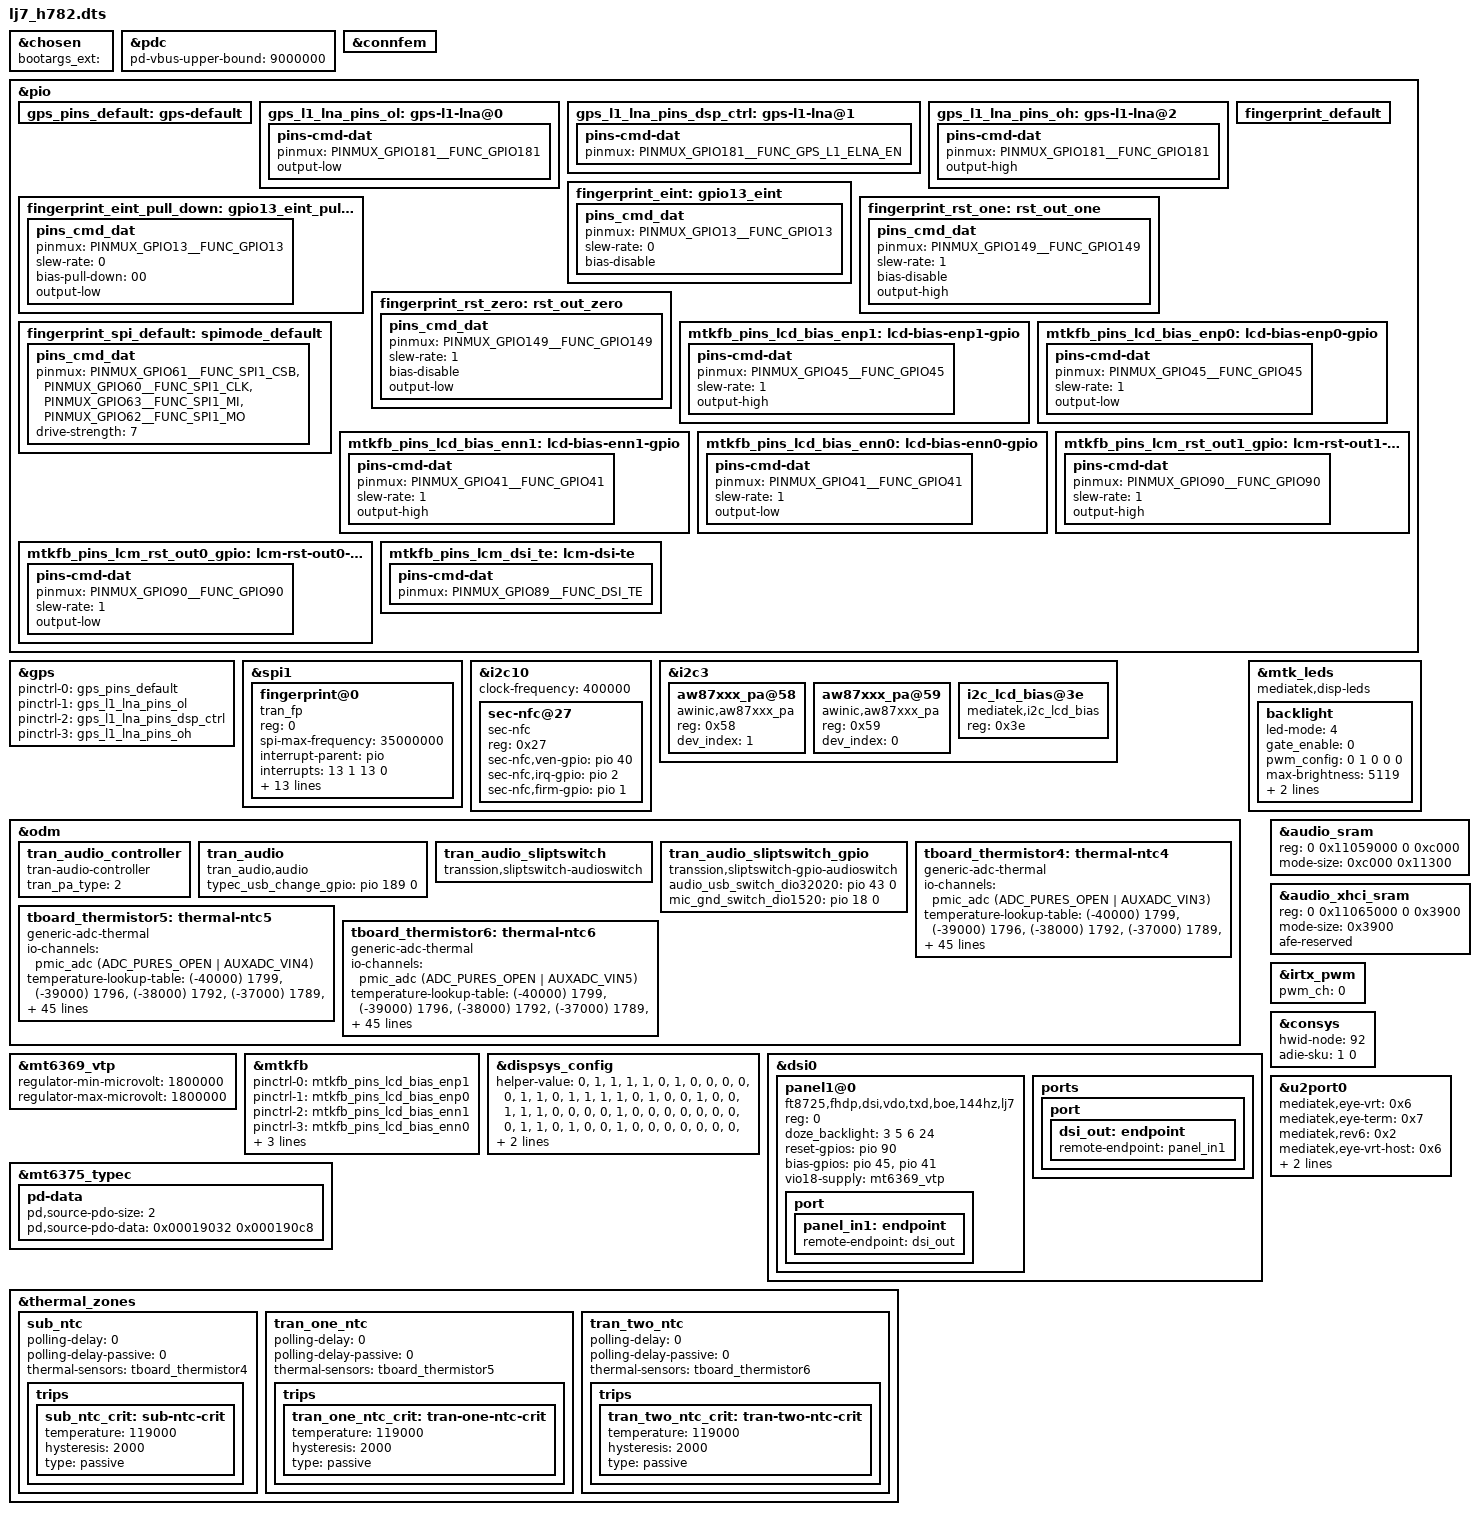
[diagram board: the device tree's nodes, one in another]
// SPDX-License-Identifier: (GPL-2.0 OR MIT)
/*
 * Copyright (C) 2022 MediaTek Inc.
 */
/dts-v1/;
/plugin/;
#include <dt-bindings/interrupt-controller/arm-gic.h>
#include <dt-bindings/interrupt-controller/irq.h>
#include <dt-bindings/phy/phy.h>
#include <dt-bindings/pinctrl/mt6878-pinfunc.h>
#include <dt-bindings/iio/mt635x-auxadc.h> 
#if 0
#include <dt-bindings/pinctrl/mt6897-pinfunc.h>
#endif

&chosen {
bootargs_ext = "";
};

&pdc {
	pd-vbus-upper-bound = <9000000>;
};

#if 1

&connfem {
/* Enable epa_elna node to support Wifi & BT ePA/eLNA FEM on customer load */
#if 0
	epa-elna {
		parts = <&wlan7207h &wlan7207c>;
		wifi {
			flags-0 {
				open-loop;
			};
		};
		bt {
			flags-0 {
				/* choose one of: epa-elna/epa/elna/bypass */
				epa-elna;
			};
		};
	};
#endif
};

/* GPS GPIO standardization start */
&pio {
	gps_pins_default: gps-default {
	};
	gps_l1_lna_pins_ol: gps-l1-lna@0 {
		pins-cmd-dat {
			pinmux = <PINMUX_GPIO181__FUNC_GPIO181>;
			output-low;
		};
	};
	gps_l1_lna_pins_dsp_ctrl: gps-l1-lna@1 {
		pins-cmd-dat {
			pinmux = <PINMUX_GPIO181__FUNC_GPS_L1_ELNA_EN>;
		};
	};
	gps_l1_lna_pins_oh: gps-l1-lna@2 {
		pins-cmd-dat {
			pinmux = <PINMUX_GPIO181__FUNC_GPIO181>;
			output-high;
		};
	};
};
&gps {
	pinctrl-names = "default",
		"gps_l1_lna_disable",
		"gps_l1_lna_dsp_ctrl",
		"gps_l1_lna_enable";
	pinctrl-0 = <&gps_pins_default>;
	pinctrl-1 = <&gps_l1_lna_pins_ol>;
	pinctrl-2 = <&gps_l1_lna_pins_dsp_ctrl>;
	pinctrl-3 = <&gps_l1_lna_pins_oh>;
	status = "okay";
};
/* GPS GPIO standardization end */

#endif

&spi1 {
    fingerprint@0 {
        compatible = "tran_fp";
        reg = <0>;
        spi-max-frequency = <35000000>;
        interrupt-parent = <&pio>;
        interrupts = <13 1 13 0>;
        debounce = <27 0>;
        irq-gpio = <13>;
        irq-gpio-std = <&pio 13 0x0>;
        reset-gpio = <149>;
        reset-gpio-std = <&pio 149 0x0>;
        vmch-supply = <&mt6369_vfp>;
        fod_location_xy = "630,2537";
        pinctrl-names ="tran_fp_default",
            "tran_fp_pin_irq",
            "tran_fp_irq_pull_down",
            "tran_fp_reset_high",
            "tran_fp_reset_low",
            "tran_fp_spi_default";
        pinctrl-0 = <&fingerprint_default>;
        pinctrl-1 = <&fingerprint_eint>;
        pinctrl-2 = <&fingerprint_eint_pull_down>;
        pinctrl-3 = <&fingerprint_rst_one>;
        pinctrl-4 = <&fingerprint_rst_zero>;
        pinctrl-5 = <&fingerprint_spi_default>;
        status = "okay";
    };
};
&pio {
    fingerprint_default: fingerprint_default {
	};
    fingerprint_eint: gpio13_eint {
    pins_cmd_dat {
        pinmux = <PINMUX_GPIO13__FUNC_GPIO13>;
        slew-rate = <0>;
        bias-disable;
        };
    };
    fingerprint_eint_pull_down: gpio13_eint_pull_down {
    pins_cmd_dat {
        pinmux = <PINMUX_GPIO13__FUNC_GPIO13>;
        slew-rate = <0>;
        bias-pull-down = <00>;
        output-low;
        };
    };
    fingerprint_rst_one: rst_out_one {
    pins_cmd_dat {
        pinmux = <PINMUX_GPIO149__FUNC_GPIO149>;
        slew-rate = <1>;
        bias-disable;
        output-high;
        };
    };
    fingerprint_rst_zero: rst_out_zero {
    pins_cmd_dat {
        pinmux = <PINMUX_GPIO149__FUNC_GPIO149>;
        slew-rate = <1>;
        bias-disable;
        output-low;
        };
    };
    fingerprint_spi_default: spimode_default {
        pins_cmd_dat {
        pinmux = <PINMUX_GPIO61__FUNC_SPI1_CSB>,
                <PINMUX_GPIO60__FUNC_SPI1_CLK>,
                <PINMUX_GPIO63__FUNC_SPI1_MI>,
                <PINMUX_GPIO62__FUNC_SPI1_MO>;
                drive-strength = <7>;
         };
     };
};

&i2c10 {
	clock-frequency = <400000>;
	sec-nfc@27 {
		compatible = "sec-nfc";
		reg = <0x27>;
		sec-nfc,ven-gpio = <&pio 40 0x0>;
		sec-nfc,irq-gpio = <&pio 2 0x0>;
		sec-nfc,firm-gpio = <&pio 1 0x0>;
	};
};

/*
&i2c6 {
	spk: speaker-amp@5c {
		compatible = "richtek,rt5512";
		#address-cells = <1>;
		#size-cells = <0>;
		#sound-dai-cells = <0>;
		reg = <0x5c>;
		status = "okay";
		sound-name-prefix = "Left";
	};
};
&sound {
	mediatek,spk-i2s = <25 24>;
};
*/
&i2c3 {
	aw87xxx_pa@58 {
		compatible = "awinic,aw87xxx_pa";
		reg = <0x58>;
		dev_index = < 1 >;
		status = "okay";
	};
	aw87xxx_pa@59 {
		compatible = "awinic,aw87xxx_pa";
		reg = <0x59>;
		dev_index = < 0 >;
		status = "okay";
	};
};

&odm {
	tran_audio_controller:tran_audio_controller {
		compatible = "tran-audio-controller";
		tran_pa_type = <2>;
	};
	tran_audio:tran_audio {
		compatible = "tran_audio,audio";
		typec_usb_change_gpio = <&pio 189 0>;
	};
	tran_audio_sliptswitch {
		compatible = "transsion,sliptswitch-audioswitch";
	};
	tran_audio_sliptswitch_gpio {
		compatible = "transsion,sliptswitch-gpio-audioswitch";
		audio_usb_switch_dio32020 = <&pio 43 0>;
		mic_gnd_switch_dio1520 = <&pio 18 0>;
	};
	tboard_thermistor4: thermal-ntc4 {
		compatible = "generic-adc-thermal";
		#thermal-sensor-cells = <0>;
		io-channels = <&pmic_adc (ADC_PURES_OPEN | AUXADC_VIN3)>;
		io-channel-names = "sensor-channel";
		temperature-lookup-table =
            <(-40000) 1799>,
			<(-39000) 1796>,
			<(-38000) 1792>,
			<(-37000) 1789>,
			<(-36000) 1786>,
			<(-35000) 1782>,
			<(-34000) 1778>,
			<(-33000) 1774>,
			<(-32000) 1769>,
			<(-31000) 1764>,
			<(-30000) 1759>,
			<(-29000) 1754>,
			<(-28000) 1749>,
			<(-27000) 1743>,
			<(-26000) 1737>,
			<(-25000) 1730>,
			<(-24000) 1723>,
			<(-23000) 1716>,
			<(-22000) 1709>,
			<(-21000) 1701>,
			<(-20000) 1692>,
			<(-19000) 1684>,
			<(-18000) 1675>,
			<(-17000) 1665>,
			<(-16000) 1655>,
			<(-15000) 1645>,
			<(-14000) 1634>,
			<(-13000) 1623>,
			<(-12000) 1612>,
			<(-11000) 1600>,
			<(-10000) 1587>,
			<(-9000) 1574>,
			<(-8000) 1561>,
			<(-7000) 1547>,
			<(-6000) 1532>,
			<(-5000) 1518>,
			<(-4000) 1502>,
			<(-3000) 1487>,
			<(-2000) 1471>,
			<(-1000) 1454>,
			<0 1437>,
			<1000 1419>,
			<2000 1402>,
			<3000 1383>,
			<4000 1365>,
			<5000 1346>,
			<6000 1326>,
			<7000 1306>,
			<8000 1286>,
			<9000 1266>,
			<10000 1245>,
			<11000 1225>,
			<12000 1203>,
			<13000 1182>,
			<14000 1161>,
			<15000 1139>,
			<16000 1117>,
			<17000 1095>,
			<18000 1073>,
			<19000 1051>,
			<20000 1029>,
			<21000 1007>,
			<22000 985>,
			<23000 963>,
			<24000 941>,
			<25000 920>,
			<26000 898>,
			<27000 876>,
			<28000 855>,
			<29000 834>,
			<30000 813>,
			<31000 792>,
			<32000 772>,
			<33000 751>,
			<34000 731>,
			<35000 712>,
			<36000 692>,
			<37000 673>,
			<38000 655>,
			<39000 636>,
			<40000 618>,
			<41000 601>,
			<42000 583>,
			<43000 566>,
			<44000 550>,
			<45000 534>,
			<46000 518>,
			<47000 502>,
			<48000 487>,
			<49000 472>,
			<50000 458>,
			<51000 444>,
			<52000 430>,
			<53000 417>,
			<54000 404>,
			<55000 392>,
			<56000 380>,
			<57000 368>,
			<58000 356>,
			<59000 345>,
			<60000 334>,
			<61000 324>,
			<62000 313>,
			<63000 303>,
			<64000 294>,
			<65000 284>,
			<66000 275>,
			<67000 267>,
			<68000 258>,
			<69000 250>,
			<70000 242>,
			<71000 234>,
			<72000 227>,
			<73000 220>,
			<74000 213>,
			<75000 206>,
			<76000 199>,
			<77000 193>,
			<78000 187>,
			<79000 181>,
			<80000 175>,
			<81000 170>,
			<82000 164>,
			<83000 159>,
			<84000 154>,
			<85000 149>,
			<86000 145>,
			<87000 140>,
			<88000 136>,
			<89000 132>,
			<90000 128>,
			<91000 124>,
			<92000 120>,
			<93000 116>,
			<94000 113>,
			<95000 109>,
			<96000 106>,
			<97000 103>,
			<98000 99>,
			<99000 96>,
			<100000 94>,
			<101000 91>,
			<102000 88>,
			<103000 85>,
			<104000 83>,
			<105000 80>,
			<106000 78>,
			<107000 76>,
			<108000 73>,
			<109000 71>,
			<110000 69>,
			<111000 67>,
			<112000 65>,
			<113000 63>,
			<114000 61>,
			<115000 60>,
			<116000 58>,
			<117000 56>,
			<118000 55>,
			<119000 53>,
			<120000 52>,
			<121000 50>,
			<122000 49>,
			<123000 47>,
			<124000 46>,
			<125000 45>;
	};

	tboard_thermistor5: thermal-ntc5 {
		compatible = "generic-adc-thermal";
		#thermal-sensor-cells = <0>;
		io-channels = <&pmic_adc (ADC_PURES_OPEN | AUXADC_VIN4)>;
		io-channel-names = "sensor-channel";
		temperature-lookup-table =
            <(-40000) 1799>,
			<(-39000) 1796>,
			<(-38000) 1792>,
			<(-37000) 1789>,
			<(-36000) 1786>,
			<(-35000) 1782>,
			<(-34000) 1778>,
			<(-33000) 1774>,
			<(-32000) 1769>,
			<(-31000) 1764>,
			<(-30000) 1759>,
			<(-29000) 1754>,
			<(-28000) 1749>,
			<(-27000) 1743>,
			<(-26000) 1737>,
			<(-25000) 1730>,
			<(-24000) 1723>,
			<(-23000) 1716>,
			<(-22000) 1709>,
			<(-21000) 1701>,
			<(-20000) 1692>,
			<(-19000) 1684>,
			<(-18000) 1675>,
			<(-17000) 1665>,
			<(-16000) 1655>,
			<(-15000) 1645>,
			<(-14000) 1634>,
			<(-13000) 1623>,
			<(-12000) 1612>,
			<(-11000) 1600>,
			<(-10000) 1587>,
			<(-9000) 1574>,
			<(-8000) 1561>,
			<(-7000) 1547>,
			<(-6000) 1532>,
			<(-5000) 1518>,
			<(-4000) 1502>,
			<(-3000) 1487>,
			<(-2000) 1471>,
			<(-1000) 1454>,
			<0 1437>,
			<1000 1419>,
			<2000 1402>,
			<3000 1383>,
			<4000 1365>,
			<5000 1346>,
			<6000 1326>,
			<7000 1306>,
			<8000 1286>,
			<9000 1266>,
			<10000 1245>,
			<11000 1225>,
			<12000 1203>,
			<13000 1182>,
			<14000 1161>,
			<15000 1139>,
			<16000 1117>,
			<17000 1095>,
			<18000 1073>,
			<19000 1051>,
			<20000 1029>,
			<21000 1007>,
			<22000 985>,
			<23000 963>,
			<24000 941>,
			<25000 920>,
			<26000 898>,
			<27000 876>,
			<28000 855>,
			<29000 834>,
			<30000 813>,
			<31000 792>,
			<32000 772>,
			<33000 751>,
			<34000 731>,
			<35000 712>,
			<36000 692>,
			<37000 673>,
			<38000 655>,
			<39000 636>,
			<40000 618>,
			<41000 601>,
			<42000 583>,
			<43000 566>,
			<44000 550>,
			<45000 534>,
			<46000 518>,
			<47000 502>,
			<48000 487>,
			<49000 472>,
			<50000 458>,
			<51000 444>,
			<52000 430>,
			<53000 417>,
			<54000 404>,
			<55000 392>,
			<56000 380>,
			<57000 368>,
			<58000 356>,
			<59000 345>,
			<60000 334>,
			<61000 324>,
			<62000 313>,
			<63000 303>,
			<64000 294>,
			<65000 284>,
			<66000 275>,
			<67000 267>,
			<68000 258>,
			<69000 250>,
			<70000 242>,
			<71000 234>,
			<72000 227>,
			<73000 220>,
			<74000 213>,
			<75000 206>,
			<76000 199>,
			<77000 193>,
			<78000 187>,
			<79000 181>,
			<80000 175>,
			<81000 170>,
			<82000 164>,
			<83000 159>,
			<84000 154>,
			<85000 149>,
			<86000 145>,
			<87000 140>,
			<88000 136>,
			<89000 132>,
			<90000 128>,
			<91000 124>,
			<92000 120>,
			<93000 116>,
			<94000 113>,
			<95000 109>,
			<96000 106>,
			<97000 103>,
			<98000 99>,
			<99000 96>,
			<100000 94>,
			<101000 91>,
			<102000 88>,
			<103000 85>,
			<104000 83>,
			<105000 80>,
			<106000 78>,
			<107000 76>,
			<108000 73>,
			<109000 71>,
			<110000 69>,
			<111000 67>,
			<112000 65>,
			<113000 63>,
			<114000 61>,
			<115000 60>,
			<116000 58>,
			<117000 56>,
			<118000 55>,
			<119000 53>,
			<120000 52>,
			<121000 50>,
			<122000 49>,
			<123000 47>,
			<124000 46>,
			<125000 45>;
	};

	tboard_thermistor6: thermal-ntc6 {
		compatible = "generic-adc-thermal";
		#thermal-sensor-cells = <0>;
		io-channels = <&pmic_adc (ADC_PURES_OPEN | AUXADC_VIN5)>;
		io-channel-names = "sensor-channel";
		temperature-lookup-table =
            <(-40000) 1799>,
			<(-39000) 1796>,
			<(-38000) 1792>,
			<(-37000) 1789>,
			<(-36000) 1786>,
			<(-35000) 1782>,
			<(-34000) 1778>,
			<(-33000) 1774>,
			<(-32000) 1769>,
			<(-31000) 1764>,
			<(-30000) 1759>,
			<(-29000) 1754>,
			<(-28000) 1749>,
			<(-27000) 1743>,
			<(-26000) 1737>,
			<(-25000) 1730>,
			<(-24000) 1723>,
			<(-23000) 1716>,
			<(-22000) 1709>,
			<(-21000) 1701>,
			<(-20000) 1692>,
			<(-19000) 1684>,
			<(-18000) 1675>,
			<(-17000) 1665>,
			<(-16000) 1655>,
			<(-15000) 1645>,
			<(-14000) 1634>,
			<(-13000) 1623>,
			<(-12000) 1612>,
			<(-11000) 1600>,
			<(-10000) 1587>,
			<(-9000) 1574>,
			<(-8000) 1561>,
			<(-7000) 1547>,
			<(-6000) 1532>,
			<(-5000) 1518>,
			<(-4000) 1502>,
			<(-3000) 1487>,
			<(-2000) 1471>,
			<(-1000) 1454>,
			<0 1437>,
			<1000 1419>,
			<2000 1402>,
			<3000 1383>,
			<4000 1365>,
			<5000 1346>,
			<6000 1326>,
			<7000 1306>,
			<8000 1286>,
			<9000 1266>,
			<10000 1245>,
			<11000 1225>,
			<12000 1203>,
			<13000 1182>,
			<14000 1161>,
			<15000 1139>,
			<16000 1117>,
			<17000 1095>,
			<18000 1073>,
			<19000 1051>,
			<20000 1029>,
			<21000 1007>,
			<22000 985>,
			<23000 963>,
			<24000 941>,
			<25000 920>,
			<26000 898>,
			<27000 876>,
			<28000 855>,
			<29000 834>,
			<30000 813>,
			<31000 792>,
			<32000 772>,
			<33000 751>,
			<34000 731>,
			<35000 712>,
			<36000 692>,
			<37000 673>,
			<38000 655>,
			<39000 636>,
			<40000 618>,
			<41000 601>,
			<42000 583>,
			<43000 566>,
			<44000 550>,
			<45000 534>,
			<46000 518>,
			<47000 502>,
			<48000 487>,
			<49000 472>,
			<50000 458>,
			<51000 444>,
			<52000 430>,
			<53000 417>,
			<54000 404>,
			<55000 392>,
			<56000 380>,
			<57000 368>,
			<58000 356>,
			<59000 345>,
			<60000 334>,
			<61000 324>,
			<62000 313>,
			<63000 303>,
			<64000 294>,
			<65000 284>,
			<66000 275>,
			<67000 267>,
			<68000 258>,
			<69000 250>,
			<70000 242>,
			<71000 234>,
			<72000 227>,
			<73000 220>,
			<74000 213>,
			<75000 206>,
			<76000 199>,
			<77000 193>,
			<78000 187>,
			<79000 181>,
			<80000 175>,
			<81000 170>,
			<82000 164>,
			<83000 159>,
			<84000 154>,
			<85000 149>,
			<86000 145>,
			<87000 140>,
			<88000 136>,
			<89000 132>,
			<90000 128>,
			<91000 124>,
			<92000 120>,
			<93000 116>,
			<94000 113>,
			<95000 109>,
			<96000 106>,
			<97000 103>,
			<98000 99>,
			<99000 96>,
			<100000 94>,
			<101000 91>,
			<102000 88>,
			<103000 85>,
			<104000 83>,
			<105000 80>,
			<106000 78>,
			<107000 76>,
			<108000 73>,
			<109000 71>,
			<110000 69>,
			<111000 67>,
			<112000 65>,
			<113000 63>,
			<114000 61>,
			<115000 60>,
			<116000 58>,
			<117000 56>,
			<118000 55>,
			<119000 53>,
			<120000 52>,
			<121000 50>,
			<122000 49>,
			<123000 47>,
			<124000 46>,
			<125000 45>;
	};
};

&i2c3 {
	i2c_lcd_bias@3e {
		compatible = "mediatek,i2c_lcd_bias";
		reg = <0x3e>;
		status = "okay";
	};
};

&mtk_leds {
	compatible = "mediatek,disp-leds";

	backlight {
		led-mode = <4>;
		gate_enable = <0>;
		pwm_config = <0 1 0 0 0>;
		max-brightness = <5119>;
		min-brightness = <0>;
		max-hw-brightness = <5119>;
	};
};


&pio {
	mtkfb_pins_lcd_bias_enp1: lcd-bias-enp1-gpio {
		pins-cmd-dat {
			pinmux = <PINMUX_GPIO45__FUNC_GPIO45>;
			slew-rate = <1>;
			output-high;
		};
	};

	mtkfb_pins_lcd_bias_enp0: lcd-bias-enp0-gpio {
		pins-cmd-dat {
			pinmux = <PINMUX_GPIO45__FUNC_GPIO45>;
			slew-rate = <1>;
			output-low;
		};
	};

	mtkfb_pins_lcd_bias_enn1: lcd-bias-enn1-gpio {
		pins-cmd-dat {
			pinmux = <PINMUX_GPIO41__FUNC_GPIO41>;
			slew-rate = <1>;
			output-high;
		};
	};

	mtkfb_pins_lcd_bias_enn0: lcd-bias-enn0-gpio {
		pins-cmd-dat {
			pinmux = <PINMUX_GPIO41__FUNC_GPIO41>;
			slew-rate = <1>;
			output-low;
		};
	};

	mtkfb_pins_lcm_rst_out1_gpio: lcm-rst-out1-gpio {
		pins-cmd-dat {
			pinmux = <PINMUX_GPIO90__FUNC_GPIO90>;
			slew-rate = <1>;
			output-high;
		};
	};

	mtkfb_pins_lcm_rst_out0_gpio: lcm-rst-out0-gpio {
		pins-cmd-dat {
			pinmux = <PINMUX_GPIO90__FUNC_GPIO90>;
			slew-rate = <1>;
			output-low;
		};
	};
	mtkfb_pins_lcm_dsi_te: lcm-dsi-te {
		pins-cmd-dat {
			pinmux = <PINMUX_GPIO89__FUNC_DSI_TE>;
		};
	};
};

&mt6369_vtp {
	regulator-min-microvolt = <1800000>;
	regulator-max-microvolt = <1800000>;
};

&mtkfb {
	pinctrl-names = "lcd_bias_enp1_gpio", "lcd_bias_enp0_gpio",
		"lcd_bias_enn1_gpio", "lcd_bias_enn0_gpio",
		"lcm_rst_out1_gpio", "lcm_rst_out0_gpio",
		"mode_te_te";
	pinctrl-0 = <&mtkfb_pins_lcd_bias_enp1>;
	pinctrl-1 = <&mtkfb_pins_lcd_bias_enp0>;
	pinctrl-2 = <&mtkfb_pins_lcd_bias_enn1>;
	pinctrl-3 = <&mtkfb_pins_lcd_bias_enn0>;
	pinctrl-4 = <&mtkfb_pins_lcm_rst_out1_gpio>;
	pinctrl-5 = <&mtkfb_pins_lcm_rst_out0_gpio>;
	pinctrl-6 = <&mtkfb_pins_lcm_dsi_te>;

	status = "okay";
};

&dispsys_config {
	helper-value = <0>, /*MTK_DRM_OPT_STAGE*/
		<1>, /*MTK_DRM_OPT_USE_CMDQ*/
		<1>, /*MTK_DRM_OPT_USE_M4U*/
		<1>, /*MTK_DRM_OPT_MMQOS_SUPPORT*/
		<1>, /*MTK_DRM_OPT_MMDVFS_SUPPORT*/
		<0>, /*MTK_DRM_OPT_SODI_SUPPORT*/
		<1>, /*MTK_DRM_OPT_IDLE_MGR*/
		<0>, /*MTK_DRM_OPT_IDLEMGR_SWTCH_DECOUPLE*/
		<0>, /*MTK_DRM_OPT_IDLEMGR_BY_REPAINT*/
		<0>, /*MTK_DRM_OPT_IDLEMGR_ENTER_ULPS*/
		<0>, /*MTK_DRM_OPT_IDLEMGR_KEEP_LP11*/
		<0>, /*MTK_DRM_OPT_DYNAMIC_RDMA_GOLDEN_SETTING*/
		<1>, /*MTK_DRM_OPT_IDLEMGR_DISABLE_ROUTINE_IRQ*/
		<1>, /*MTK_DRM_OPT_IDLEMGR_ASYNC*/
		<0>, /*MTK_DRM_OPT_MET_LOG*/
		<1>, /*MTK_DRM_OPT_USE_PQ*/
		<1>, /*MTK_DRM_OPT_ESD_CHECK_RECOVERY*/
		<1>, /*MTK_DRM_OPT_ESD_CHECK_SWITCH*/
		<1>, /*MTK_DRM_OPT_PRESENT_FENCE*/
		<0>, /*MTK_DRM_OPT_RDMA_UNDERFLOW_AEE*/
		<1>, /*MTK_DRM_OPT_DSI_UNDERRUN_AEE*/
		<0>, /*MTK_DRM_OPT_ODDMR_OD_AEE*/
		<0>, /*MTK_DRM_OPT_ODDMR_DMR_AEE*/
		<1>, /*MTK_DRM_OPT_HRT*/
		<0>, /*MTK_DRM_OPT_HRT_MODE*/
		<0>, /*MTK_DRM_OPT_DELAYED_TRIGGER*/
		<1>, /*MTK_DRM_OPT_OVL_EXT_LAYER*/
		<1>, /*MTK_DRM_OPT_AOD*/
		<1>, /*MTK_DRM_OPT_RPO*/
		<0>, /*MTK_DRM_OPT_DUAL_PIPE*/
		<0>, /*MTK_DRM_OPT_DC_BY_HRT*/
		<0>, /*MTK_DRM_OPT_OVL_WCG*/
		<0>, /*MTK_DRM_OPT_OVL_SBCH*/
		<1>, /*MTK_DRM_OPT_COMMIT_NO_WAIT_VBLANK*/
		<0>, /*MTK_DRM_OPT_MET*/
		<0>, /*MTK_DRM_OPT_REG_PARSER_RAW_DUMP*/
		<0>, /*MTK_DRM_OPT_VP_PQ*/
		<0>, /*MTK_DRM_OPT_GAME_PQ*/
		<0>, /*MTK_DRM_OPT_MMPATH*/
		<0>, /*MTK_DRM_OPT_HBM*/
		<0>, /*MTK_DRM_OPT_VDS_PATH_SWITCH*/
		<0>, /*MTK_DRM_OPT_LAYER_REC*/
		<1>, /*MTK_DRM_OPT_CLEAR_LAYER*/
		<1>, /*MTK_DRM_OPT_LFR*/
		<0>, /*MTK_DRM_OPT_SF_PF*/
		<1>, /*MTK_DRM_OPT_DYN_MIPI_CHANGE*/
		<0>, /*MTK_DRM_OPT_PRIM_DUAL_PIPE*/
		<0>, /*MTK_DRM_OPT_MSYNC2_0*/
		<1>, /*MTK_DRM_OPT_MML_PRIMARY*/
		<0>, /*MTK_DRM_OPT_MML_SUPPORT_CMD_MODE*/
		<0>, /*MTK_DRM_OPT_MML_PQ*/
		<0>, /*MTK_DRM_OPT_MML_IR*/
		<0>, /*MTK_DRM_OPT_DUAL_TE*/
		<0>, /*MTK_DRM_OPT_RES_SWITCH*/
		<0>, /*MTK_DRM_OPT_PREFETCH_TE*/
		<0>, /*MTK_DRM_OPT_VIDLE_APSRC_OFF*/
		<0>, /*MTK_DRM_OPT_VIDLE_DSI_PLL_OFF*/
		<0>, /*MTK_DRM_OPT_CHECK_TRIGGER_MERGE*/
		<0>, /*MTK_DRM_OPT_VIRTUAL_DISP*/
		<1>, /*MTK_DRM_OPT_OVL_BW_MONITOR*/
		<0>, /*MTK_DRM_OPT_GPU_CACHE*/
		<1>, /*MTK_DRM_OPT_SPHRT*/
		<1>, /*MTK_DRM_OPT_SDPA_OVL_SWITCH*/
		<0>, /*MTK_DRM_OPT_HRT_BY_LARB*/
		<1>, /*MTK_DRM_OPT_LAYERING_RULE_BY_LARB*/
		<1>, /*MTK_DRM_OPT_RES_SWITCH_ON_AP*/
		<0>, /*MTK_DRM_OPT_TILE_OVERHEAD*/
		<1>, /*MTK_DRM_OPT_VIDLE_TOP_EN*/
		<0>, /*MTK_DRM_OPT_VIDLE_MTCMOS_DT_EN*/
		<1>, /*MTK_DRM_OPT_VIDLE_MMINFRA_DT_EN*/
		<0>, /*MTK_DRM_OPT_VIDLE_DVFS_DT_EN*/
		<0>, /*MTK_DRM_OPT_VIDLE_QOS_DT_EN*/
		<0>, /*MTK_DRM_OPT_VIDLE_GCE_TS_EN*/
		<0>, /*MTK_DRM_OPT_VIDLE_DECOUPLE_MODE*/
		<0>, /*MTK_DRM_OPT_VIDLE_VDO_PANEL*/
		<0>, /*MTK_DRM_OPT_VIDLE_HOME_SCREEN_IDLE*/
		<0>, /*MTK_DRM_OPT_DPC_PRE_TE_EN*/
		<0>; /*"MTK_DRM_OPT_PER_LARB_PORT_PEAK"*/
};

&dsi0 {
	status = "okay";
	#address-cells = <1>;
	#size-cells = <0>;
	panel1@0 {
		compatible = "ft8725,fhdp,dsi,vdo,txd,boe,144hz,lj7";
		reg = <0>;
		doze_backlight = <3 5 6 24>;
		reset-gpios = <&pio 90 0>;
		bias-gpios = <&pio 45 0>, <&pio 41 0>;
		vio18-supply = <&mt6369_vtp>;
		pinctrl-names = "default";
		port {
			panel_in1: endpoint {
				remote-endpoint = <&dsi_out>;
			};
		};
	};

	ports {
		port {
			dsi_out: endpoint {
				remote-endpoint = <&panel_in1>;
			};
		};
	};
};
&audio_sram {
	reg = <0 0x11059000 0 0xc000>;
	mode-size = <0xc000 0x11300>;
};

&audio_xhci_sram {
	reg = <0 0x11065000 0 0x3900>;
	mode-size = <0x3900>;
	afe-reserved;
};

/* usb typec mux start */
&mt6375_typec {
	//tcpc,en-fod;
	pd-data {
		/*
		 * Fixed 5V, 500 mA <0x00019032>
		 * Fixed 5V, 1A <0x00019064>
		 * Fixed 5V, 1.5A <0x00019096>
		 * Fixed 5V, 2A <0x000190c8>
		 * Fixed 5V, 3A <0x0001912c>
		 * Fixed 9V, 500 mA <0x0002d032>
		 * Fixed 9V, 1A <0x0002d064>
		 * Fixed 9V, 2A <0x0002d0c8>
		 * Fixed 9V, 3A <0x0002d12c>
		 * Variable 5-9V, 1A <0x8642d064>
		 * Variable 5-9V, 2A <0x8642d0c8>
		 * Variable 5-9V, 3A <0x8642d12c>
		 * PPS 3V~5.9V, 3A <0xC0761E3C>
		 */
		pd,source-pdo-size = <2>;
		pd,source-pdo-data = <0x00019032 0x000190c8>; /* 1:5V,500mA  2:5V,2000 mA */
	};
};

&pdc {
	pd-vbus-upper-bound = <9000000>;
};

&irtx_pwm {
	pwm_ch = <0>;
	status = "okay";
};

&consys {
	hwid-node = <92>;
	adie-sku = <1 0>;
};

&thermal_zones {
	sub_ntc: sub_ntc {
		polling-delay = <0>; /* milliseconds */
		polling-delay-passive = <0>; /* milliseconds */
		thermal-sensors = <&tboard_thermistor4>;

		trips {
			sub_ntc_crit: sub-ntc-crit {
				temperature = <119000>;
				hysteresis = <2000>;
				type = "passive";
			};
		};
	};
	tran_one_ntc: tran_one_ntc {
		polling-delay = <0>; /* milliseconds */
		polling-delay-passive = <0>; /* milliseconds */
		thermal-sensors = <&tboard_thermistor5>;

		trips {
			tran_one_ntc_crit: tran-one-ntc-crit {
				temperature = <119000>;
				hysteresis = <2000>;
				type = "passive";
			};
		};
	};
	tran_two_ntc: tran_two_ntc {
		polling-delay = <0>; /* milliseconds */
		polling-delay-passive = <0>; /* milliseconds */
		thermal-sensors = <&tboard_thermistor6>;

		trips {
			tran_two_ntc_crit: tran-two-ntc-crit {
				temperature = <119000>;
				hysteresis = <2000>;
				type = "passive";
			};
		};
	};
};

&u2port0 {
        mediatek,eye-vrt = <0x6>;
        mediatek,eye-term = <0x7>;
        mediatek,rev6 = <0x2>;
        mediatek,eye-vrt-host = <0x6>;
        mediatek,eye-term-host = <0x7>;
        mediatek,rev6-host = <0x2>;
};

#include "mediatek/charge/lj7_h782/mt6375_typec.dtsi"
#include "mediatek/charge/lj7_h782/tc_hl7139a.dtsi"
#include "mediatek/charge/lj7_h782/tran_usb_ctrl.dtsi"
#include "mediatek/charge/lj7_h782/tc_pe50.dtsi"
#include "mediatek/charge/lj7_h782/protocol_ta.dtsi"
#include "mediatek/charge/lj7_h782/tc_charger.dtsi"
#include "mediatek/charge/lj7_h782/tc_charger_lk.dtsi"
#include "mediatek/charge/lj7_h782/cps4021.dtsi"
#include "mediatek/charge/lj7_h782/bat_setting/mt6878_battery_prop.dtsi"
#include <lj7_h782/cust.dtsi>
#include "mediatek/tc_led.dtsi"
#include "mediatek/led/lj7_h782/tran_led_aw20144_lj7.dtsi"
#include "mediatek/touch/lj7_h782/tran_mt6878_touch_lj7.dtsi"
#include "mediatek/msdc/lj7_h782/cust_mt6878_msdc.dtsi"
#include "mediatek/camera/lj7/cust_mt6878_camera_v4l2.dtsi"
#include "mediatek/cust_k6878_connfem.dtsi"
#include "sensor/tran_mt6881_lj7_h782_sensor.dtsi"
/*End of this file, DO NOT ADD ANYTHING HERE*/

